# CMS32M67xx register map
Vendor: CMS; Series: CMS32M67xx; File version: 1.2
CPU: CM0+ r0p1, little endian, no MPU, no FPU, VTOR, 2 interrupt priority bits
Registers are 32-bit, read-write, reset 0x0 unless marked. A register's access mark holds for its fields unless they carry their own. Offsets are from the block's base; [hi:lo] are bit positions; {n}, {i} and the like mark numbered series; 'fields as' and 'values as' point back to an identical list.

## LVD — Voltage detector
Base 0x40020440
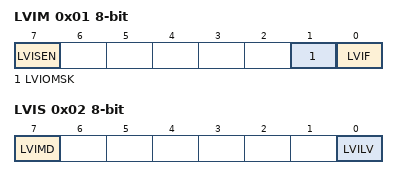
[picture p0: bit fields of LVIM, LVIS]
0x01 LVIM 8-bit — Voltage detection register
  [7] LVISEN ro — Enable rewritting LVIS register
    0=Disable (Disabling of rewriting the LVIS register); 1=Enable (Enabling of rewriting the LVIS register)
  [1] LVIOMSK ro — Mask status flag of LVD output
    0=Invalid (Mask of LVD output is invalid); 1=Valid (Mask of LVD output is valid)
  [0] LVIF ro — Voltage detection flag
    0=GE (Supply voltage (VDD) greater or equal to detection voltage (VLVD), or when LVD is off); 1=LT (Supply voltage (VDD) less than detection voltage (VLVD))
0x02 LVIS 8-bit — Voltage detection level register
  [7] LVIMD — Operation mode of voltage detection
    0=IRQ (interrupt mode); 1=reset mode
  [0] LVILV — LVD detection level
    0=High-voltage detection level (VLVDH); 1=Low (Low-voltage detection level (VLVDL or VLVD))

## PCBZ — Clock/Buzzer output controller
Base 0x40040FA0
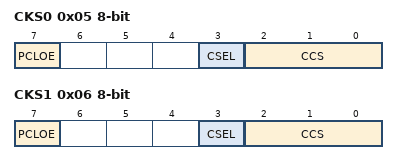
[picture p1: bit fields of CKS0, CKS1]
0x05 CKS0 8-bit — Clock output select registers 0
  [7] PCLOE — PCLBUZn pin output enable
  [3] CSEL — PCLBUZn output clock select
  [2:0] CCS — PCLBUZn output clock select
0x06 CKS1 8-bit — Clock output select registers 1
  fields as CKS0

## WDT — Watchdog Timer with window
Base 0x40020404
0x01 LOCKCTL 8-bit (reset mask 0x1) — Lockup Watchdog timer enable register
0x02 PRCR 8-bit — Lockup Watchdog timer enable protect register
0xBFD WDTE 8-bit (reset mask 0xAC) — Watchdog timer enable register

## TIMER0 — TIMER0 Decription
Base 0x40061000
Same registers: TIMER1 0x40061100
0x00 CON reset 0x20 — CON Description
0x04 LOAD — LOAD Description
0x08 VAL ro reset 0xFFFFFFFF — VAL Description
0x0C RIS ro — RIS Description
0x10 MIS ro — MIS Description
0x14 ICLR wo — ICLR Description
0x18 BGLOAD — BGLOAD Description

## LSITIMER
Base 0x40044B50
0x00 CON0 16-bit — Control Register 0

## EPWM — EPWM Decription
Base 0x40064200
0x00 CLKPSC — CLKPSC Description
0x04 CLKDIV — CLKDIV Description
0x08 CON — CON Description
{0x4+4i} CON{i} (i=2..4) — CON{i} Description
{0x18+4i} PERIOD{i} (i=0..7) — PERIOD{i} Description
{0x38+4i} CMPDAT{i} (i=0..7) — CMPDAT{i} Description
0x58 POREMAP_EN — POREMAP_EN Description
0x5C POREMAP — POREMAP Description
0x60 POEN reset 0x543210 — POEN Description
0x64 BRKCTL — BRKCTL Description
0x68 MASK — MASK Description
0x6C MASKNXT — MASKNXT Description
0x70 CMPTGD0 — CMPTGD0 Description
0x74 CMPTGD1 — CMPTGD1 Description
0x78 IMSC — IMSC Description
0x7C IMSC2 — IMSC2 Description
0x80 RIS ro — RIS Description
0x84 RIS2 ro — RIS2 Description
0x88 MIS ro — MIS Description
0x8C MIS2 ro — MIS2 Description
0x90 ICLR wo — ICLR Description
0x94 ICLR2 wo — ICLR2 Description
0x98 IFA — IFA Description
0x9C LOCK — LOCK Description
0xA0 BRKRDT — BRKRDT Description
0xA4 DTCTL01 — DTCTL01 Description
0xA8 DTCTL23 — DTCTL23 Description
0xAC DTCTL45 — DTCTL45 Description
0xB0 DTCTL67 — DTCTL67 Description

## CCP — CCP Decription
Base 0x40064300
0x00 CCPCON0 — CCPCON0 Description
0x04 CCPLOAD0 — CCPLOAD0 Description
0x08 CCPD0A — CCPD0A Description
0x0C CCPD0B — CCPD0B Description
0x10 CCPCON1 — CCPCON1 Description
0x14 CCPLOAD1 — CCPLOAD1 Description
0x18 CCPD1A — CCPD1A Description
0x1C CCPD1B — CCPD1B Description
0x40 CCPIMSC — CCPIMSC Description
0x44 CCPRIS ro — CCPRIS Description
0x48 CCPMIS ro — CCPMIS Description
0x4C CCPICLR wo — CCPICLR Description
0x50 CCPRUN — CCPRUN Description
0x54 CCPLOCK — CCPLOCK Description
0x58 CAPCON — CAPCON Description
0x5C CAPCON2 — CAPCON2 Description
0x60 CAPCON3 — CAPCON3 Description
0x64 CAPCHS — CAPCHS Description
0x68 CAP0DAT0 — CAP0DAT0 Description
{0x68+4i} CAP{i}DAT0 ro (i=1..3) — CAP{i}DAT0 Description
0x78 CAPDUTY ro — CAPDUTY Description
